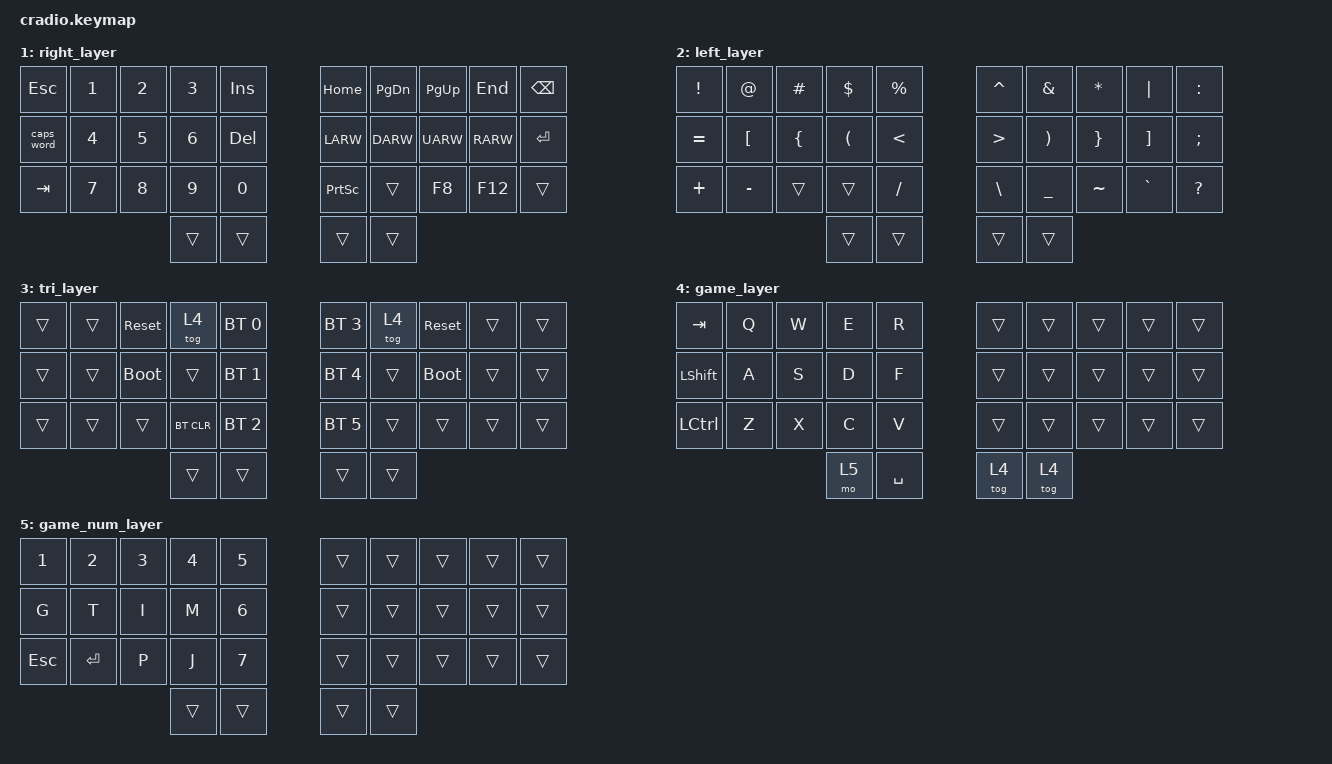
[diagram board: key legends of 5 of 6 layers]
// Copyright (c) 2022 The ZMK Contributors
// SPDX-License-Identifier: MIT

#include <behaviors.dtsi>
#include <dt-bindings/zmk/keys.h>
#include <dt-bindings/zmk/bt.h>

// Home row mods macro
#define HRML(k1,k2,k3,k4) &ht LSHFT k1 &ht LCTRL k2  &ht LGUI k3 &ht LALT k4
#define HRMR(k1,k2,k3,k4) &ht RALT k1  &ht RGUI k2  &ht RCTRL k3  &ht RSHFT k4

&lt {
    tapping-term-ms = <150>;
};

&mt {
    tapping-term-ms = <150>;
};

/ {
    behaviors {
        ht: hold_tap {
            label = "hold_tap";
            compatible = "zmk,behavior-hold-tap";
            #binding-cells = <2>;
            flavor = "tap-preferred";
            tapping-term-ms = <200>;
            quick-tap-ms = <150>;
            require-prior-idle-ms = <100>;
            bindings = <&kp>, <&kp>;
        };
    };

    conditional_layers {
        compatible = "zmk,conditional-layers";
        tri_layer {
            if-layers = <1 2>;
            then-layer = <3>;
        };
    };

    keymap {
        compatible = "zmk,keymap";
        default_layer {
            bindings = <
        //╭──────────┬──────────┬──────────┬──────────┬──────────╮   ╭──────────┬──────────┬──────────┬──────────┬──────────╮
        //│  Q       │  W       │  E       │  R       │  T       │   │  Y       │  U       │  I       │  O       │  P       │
            &kp Q      &kp W      &kp E      &kp R      &kp T          &kp Y      &kp U      &kp I      &kp O      &kp P
        //├──────────┼──────────┼──────────┼──────────┼──────────┤   ├──────────┼──────────┼──────────┼──────────┼──────────┤
        //│  A       │  S       │  D       │  F       │  G       │   │  H       │  J       │  K       │  L       │ ' "      │
            HRML(A,        S,         D,         F)     &kp G          &kp H      HRMR(J,        K,         L,        SQT)
        //├──────────┼──────────┼──────────┼──────────┼──────────┤   ├──────────┼──────────┼──────────┼──────────┼──────────┤
        //│LEFT SHIFT|  Z       │  X       │  C       │  V       │   | B        │  N       │  M       │ , <      │ . >      │
           &kp LSHFT  &kp Z     &kp X      &kp C      &kp V            &kp B     &kp N      &kp M      &kp COMMA  &kp DOT
        //╰──────────┴──────────┴──────────┼──────────┼──────────┤   ├──────────┼──────────┼──────────┴──────────┴──────────╯
                                       &mt LSHFT SPACE &lt 2 SPACE   &lt 1 SPACE &mt RSHFT SPACE
        //                                 ╰──────────┴──────────╯   ╰──────────┴──────────╯
            >;
        };

        right_layer {
            bindings = <
        //╭──────────┬──────────┬──────────┬──────────┬──────────╮   ╭──────────┬──────────┬──────────┬──────────┬──────────╮
        //│ ESC      │  1       │  2       │  3       │  INSERT  │   │ HOME     │ PAGE DN  │ PAGE UP  │ END      │BACKSPACE │
            &kp ESC    &kp N1     &kp N2     &kp N3     &kp INS        &kp HOME   &kp PG_DN  &kp PG_UP  &kp END   &kp BSPC
        //├──────────┼──────────┼──────────┼──────────┼──────────┤   ├──────────┼──────────┼──────────┼──────────┼──────────┤
        //│ CAPS     │  4       │  5       │  6       │  DELETE  │   │ LEFT     │ DOWN     │ UP       │ RIGHT    │   ENTER  │
           &caps_word  &kp N4     &kp N5     &kp N6     &kp DEL       &kp LARW   &kp DARW   &kp UARW   &kp RARW   &kp ENTER
        //├──────────┼──────────┼──────────┼──────────┼──────────┤   ├──────────┼──────────┼──────────┼──────────┼──────────┤
        //│   TAB    │  7       │  8       │  9       │  0       │   │PRINT SCR │          │    F8    │    F12   │          │
           &kp TAB     &kp N7     &kp N8     &kp N9     &kp N0         &kp PSCRN   &trans     &kp F8     &kp F12    &trans
        //╰──────────┴──────────┴──────────┼──────────┼──────────┤   ├──────────┼──────────┼──────────┴──────────┴──────────╯
                                             &trans     &trans        &trans     &trans
        //                                 ╰──────────┴──────────╯   ╰──────────┴──────────╯
            >;
        };

        left_layer {
            bindings = <
        //╭──────────┬──────────┬──────────┬──────────┬──────────╮   ╭──────────┬──────────┬──────────┬──────────┬──────────╮
        //│  !       │  @       │  #       │  $       │  %       │   │  ^       │  &       │  *       │  │       │   :      │
            &kp EXCL   &kp AT     &kp HASH   &kp DLLR   &kp PRCNT     &kp CARET  &kp AMPS   &kp ASTRK   &kp PIPE   &kp COLON 
        //├──────────┼──────────┼──────────┼──────────┼──────────┤   ├──────────┼──────────┼──────────┼──────────┼──────────┤
        //│  =       │    [     │   {      │    (     │    <     │   │    >     │    )     │    }     │  ]       │   ;      │
            &kp EQUAL  &kp LBKT   &kp LBRC   &kp LPAR   &kp LT           &kp GT   &kp RPAR   &kp RBRC   &kp RBKT    &kp SEMI
        //├──────────┼──────────┼──────────┼──────────┼──────────┤   ├──────────┼──────────┼──────────┼──────────┼──────────┤
        //│  +       |   -      │          │          │    /     │   |    \     │  _       │   ~      │  `       │    ?     │
            &kp PLUS  &kp MINUS   &trans     &trans     &kp FSLH       &kp BSLH   &kp UNDER  &kp TILDE  &kp GRAVE  &kp QMARK
        //╰──────────┴──────────┴──────────┼──────────┼──────────┤   ├──────────┼──────────┼──────────┴──────────┴──────────╯
                                             &trans     &trans         &trans     &trans
        //                                 ╰──────────┴──────────╯   ╰──────────┴──────────╯
            >;
        };

        tri_layer {
            bindings = <
        //╭──────────┬──────────┬──────────┬──────────┬──────────╮   ╭──────────┬──────────┬──────────┬──────────┬──────────╮
        //│          │          │  RESET   │   GAME   │PROFILE 0 │   │PROFILE 3 │   GAME   │  RESET   │          │          │
            &trans     &trans    &sys_reset  &tog 4    &bt BT_SEL 0  &bt BT_SEL 3  &tog 4   &sys_reset  &trans     &trans    
        //├──────────┼──────────┼──────────┼──────────┼──────────┤   ├──────────┼──────────┼──────────┼──────────┼──────────┤
        //│          │          │BOOTLOADER│          │PROFILE 1 │   │PROFILE 4 │          │BOOTLOADER│          │          │
            &trans     &trans    &bootloader &trans    &bt BT_SEL 1  &bt BT_SEL 4 &trans    &bootloader  &trans   &trans    
        //├──────────┼──────────┼──────────┼──────────┼──────────┤   ├──────────┼──────────┼──────────┼──────────┼──────────┤
        //│          │          │          │ CLEAR BT │PROFILE 2 │   │PROFILE 5 │          │          │          │          │
            &trans     &trans     &trans    &bt BT_CLR &bt BT_SEL 2  &bt BT_SEL 5 &trans     &trans     &trans     &trans
        //╰──────────┴──────────┴──────────┼──────────┼──────────┤   ├──────────┼──────────┼──────────┴──────────┴──────────╯
                                             &trans     &trans         &trans     &trans
        //                                 ╰──────────┴──────────╯   ╰──────────┴──────────╯
            >;
        };

        game_layer {
            bindings = <
        //╭──────────┬──────────┬──────────┬──────────┬──────────╮   ╭──────────┬──────────┬──────────┬──────────┬──────────╮
        //│    TAB   |  Q       │  W       │  E       │  R       │   │          │          │          │          │          |
            &kp TAB   &kp Q      &kp W      &kp E      &kp R           &trans     &trans     &trans      &trans     &trans  
        //├──────────┼──────────┼──────────┼──────────┼──────────┤   ├──────────┼──────────┼──────────┼──────────┼──────────┤
        //│LEFT SHIFT|  A       │  S       │  D       │  F       │   │          │          │          │          │          |
            &kp LSHFT  &kp A      &kp S      &kp D      &kp F          &trans     &trans     &trans      &trans     &trans
        //├──────────┼──────────┼──────────┼──────────┼──────────┤   ├──────────┼──────────┼──────────┼──────────┼──────────┤
        //│LEFT CTRL |  Z       │  X       │  C       │  V       │   │          │          │          │          │          |
            &kp LCTRL  &kp Z     &kp X      &kp C      &kp V            &trans     &trans     &trans      &trans     &trans
        //╰──────────┴──────────┴──────────┼──────────┼──────────┤   ├──────────┼──────────┼──────────┴──────────┴──────────╯
                                            &mo  5      &kp SPACE       &tog 4    &tog 4
        //                                 ╰──────────┴──────────╯   ╰──────────┴──────────╯
            >;
        };

        game_num_layer {
            bindings = <
        //╭──────────┬──────────┬──────────┬──────────┬──────────╮   ╭──────────┬──────────┬──────────┬──────────┬──────────╮
        //│    1     |    2     │    3     │    4     │    5     │   │          │          │          │          │          |
             &kp N1     &kp N2     &kp N3     &kp N4     &kp N5         &trans     &trans     &trans      &trans     &trans  
        //├──────────┼──────────┼──────────┼──────────┼──────────┤   ├──────────┼──────────┼──────────┼──────────┼──────────┤
        //│    G     │    T     |    I     │    M     │    6     │   |          │          │          │          │          |
            &kp G       &kp T    &kp I      &kp M      &kp N6         &trans     &trans     &trans      &trans     &trans
        //├──────────┼──────────┼──────────┼──────────┼──────────┤   ├──────────┼──────────┼──────────┼──────────┼──────────┤
        //│   ESC    │   ENTER  │    P     │    J     │    7     |   │          │          │          │          │          |
            &kp ESC    &kp ENTER   &kp P     &kp J      &kp N7        &trans     &trans     &trans      &trans     &trans
        //╰──────────┴──────────┴──────────┼──────────┼──────────┤   ├──────────┼──────────┼──────────┴──────────┴──────────╯
                                              &trans     &trans         &trans     &trans
        //                                 ╰──────────┴──────────╯   ╰──────────┴──────────╯
            >;
        };
    };
};
